# LPC844 register map
Vendor: nxp.com; File version: 1.0
CPU: CM0PLUS r0p0, little endian, no MPU, no FPU, VTOR, 2 interrupt priority bits
Registers are 32-bit, read-write, reset 0x0 unless marked. A register's access mark holds for its fields unless they carry their own. Offsets are from the block's base; [hi:lo] are bit positions; {n}, {i} and the like mark numbered series.

## INPUTMUX — LPC84x Input multiplexing (INPUT MUX)
Base 0x4002C000
{0x0+4i} DMA_INMUX_INMUX[{i}] (i=0..1) reset 0x1F — DMA output trigger selection to become DMA trigger
  [4:0] INP — DMA trigger output number (decimal value) for DMA channel n (n = 0 to 24).
{0x20+4i} SCT_INMUX[{i}] (i=0..3) reset 0xF — input select register for SCT
  [3:0] INP_N — Input mux register for SCT input n (n = 0 to 3). 0 = sct input 0 1=sct input 1 2= sct input 2 3= sct gpio input 3 4= adc_thcmp_irq 5 = comparator out 6 = timer ct32b0 match2 7=gpio_int_bmatch 8=arm_txev 9=debug_halted
{0x40+4i} DMA_ITRIG_INMUX[{i}] (i=0..24) reset 0xF — Trigger select register for DMA channel
  [3:0] INP — Trigger input number (decimal value) for DMA channel n (n = 0 to 12). 0 = ADC0 Sequence A interrupt 1 = ADC0 Sequence B interrupt 2 = SCT0 DMA request 0 3 = SCT0 DMA request 1 4= Comparator out 5 = Pin interrupt 4 6 = Pin interrupt 5 7 = Pin interrupt 6 8 = Pin interrupt 7 9= Timer CTIMER0 Match 0 dma request 10 = Timer CTIMER0 Match 1 dma request 11 = DMA output trigger mux 0 12 = DMA output trigger mux 1

## FLASH_CTRL — LPC84x NVMC flash controller
Base 0x40040000
0x10 FLASHCFG reset 0x2 — Flash configuration register
  [1:0] FLASHTIM — Flash memory access time. FLASHTIM +1 is equal to the number of system clocks used for flash access.
    0=ONE_SYSTEM_CLOCK_FLASH_ACCESS (1 system clock flash access time.); 1=TWO_SYSTEM_CLOCK_FLASH_ACCESS (2 system clock flash access time.); 2=THREE_SYSTEM_CLOCK_FLASH_ACCESS (3 system clock flash access time.)
0x20 FMSSTART — Flash signature start address register
  [16:0] START — Signature generation start address (corresponds to AHB byte address bits[18:2]).
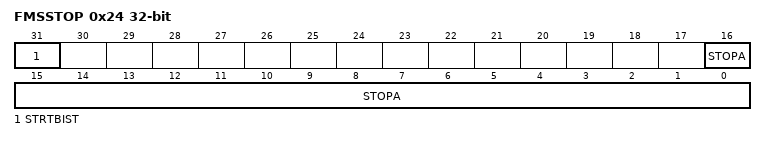
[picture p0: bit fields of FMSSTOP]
0x24 FMSSTOP — Flash signaure stop address register
  [31] STRTBIST — When this bit is written to 1, signature generation starts. At the end of signature generation, this bit is automatically cleared.
  [16:0] STOPA — Stop address for signature generation (the word specified by STOP is included in the address range). The address is in units of memory words, not bytes.
0x2C FMSW0 ro reset not defined — Flash signature generation result register returns the flash signature produced by the embedded signature generator..
  [31:0] SIG — 32-bit signature.
0xFE0 FMSTAT ro — Flash signature generation status bit
  [1] SIG_DONE — This status bit is set at the end of signature computation
0xFE8 FMSTATCLR wo — Clear FLASH signature generation status bit
  [1] SIG_DONE_CLR — When the bit is written to 1, the SIGNATURE_DONE bit is cleared.

## CRC — LPC5411x CRC engine
Base 0x50000000
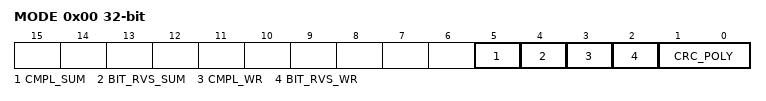
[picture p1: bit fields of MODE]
0x00 MODE — CRC mode register
  [5] CMPL_SUM — CRC sum complement: 1 = 1's complement for CRC_SUM 0 = No 1's complement for CRC_SUM
  [4] BIT_RVS_SUM — CRC sum bit order: 1 = Bit order reverse for CRC_SUM 0 = No bit order reverse for CRC_SUM
  [3] CMPL_WR — Data complement: 1 = 1's complement for CRC_WR_DATA 0 = No 1's complement for CRC_WR_DATA
  [2] BIT_RVS_WR — Data bit order: 1 = Bit order reverse for CRC_WR_DATA (per byte) 0 = No bit order reverse for CRC_WR_DATA (per byte)
  [1:0] CRC_POLY — CRC polynomial: 1X = CRC-32 polynomial 01 = CRC-16 polynomial 00 = CRC-CCITT polynomial
0x04 SEED reset 0xFFFF — CRC seed register
  [31:0] CRC_SEED — A write access to this register will load CRC seed value to CRC_SUM register with selected bit order and 1's complement pre-processes. A write access to this register will overrule the CRC calculation in progresses.
0x08 SUM ro reset 0xFFFF (SUM_WR_DATA view) — CRC checksum register
  [31:0] CRC_SUM — The most recent CRC sum can be read through this register with selected bit order and 1's complement post-processes.
0x08 WR_DATA wo reset not defined (SUM_WR_DATA view) — CRC data register
  [31:0] CRC_WR_DATA — Data written to this register will be taken to perform CRC calculation with selected bit order and 1's complement pre-process. Any write size 8, 16 or 32-bit are allowed and accept back-to-back transactions.
